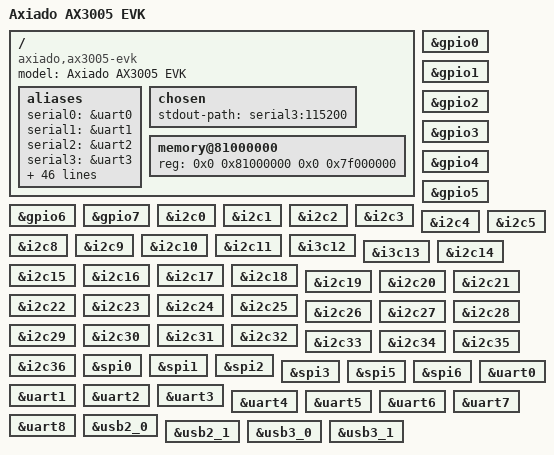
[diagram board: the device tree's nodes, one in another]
// SPDX-License-Identifier: GPL-2.0+
/*
 * DTS file for Axiado AX3005 SoC based EVK
 * Copyright (c) 2026 Axiado Corporation.
 */

/dts-v1/;

#include "ax3005.dtsi"

/ {
	model = "Axiado AX3005 EVK";
	compatible = "axiado,ax3005-evk", "axiado,ax3005";
	#address-cells = <2>;
	#size-cells = <2>;

	aliases {
		serial0 = &uart0;
		serial1 = &uart1;
		serial2 = &uart2;
		serial3 = &uart3;
		serial4 = &uart4;
		serial5 = &uart5;
		serial6 = &uart6;
		serial7 = &uart7;
		serial8 = &uart8;
		i2c0 = &i2c0;
		i2c1 = &i2c1;
		i2c2 = &i2c2;
		i2c3 = &i2c3;
		i2c4 = &i2c4;
		i2c5 = &i2c5;
		i2c8 = &i2c8;
		i2c9 = &i2c9;
		i2c10 = &i2c10;
		i2c11 = &i2c11;
		i2c12 = &i3c12;
		i2c13 = &i3c13;
		i2c14 = &i2c14;
		i2c15 = &i2c15;
		i2c16 = &i2c16;
		i2c17 = &i2c17;
		i2c18 = &i2c18;
		i2c19 = &i2c19;
		i2c20 = &i2c20;
		i2c21 = &i2c21;
		i2c22 = &i2c22;
		i2c23 = &i2c23;
		i2c24 = &i2c24;
		i2c25 = &i2c25;
		i2c26 = &i2c26;
		i2c27 = &i2c27;
		i2c28 = &i2c28;
		i2c29 = &i2c29;
		i2c30 = &i2c30;
		i2c31 = &i2c31;
		i2c32 = &i2c32;
		i2c33 = &i2c33;
		i2c34 = &i2c34;
		i2c35 = &i2c35;
		i2c36 = &i2c36;
		spi0 = &spi0;
		spi1 = &spi1;
		spi2 = &spi2;
		spi3 = &spi3;
		spi5 = &spi5;
		spi6 = &spi6;
	};

	chosen {
		stdout-path = "serial3:115200";
	};

	memory@81000000 {
		device_type = "memory";
		/* Cortex-A53 will use following memory map */
		reg = <0x0 0x81000000 0x0 0x7f000000>;
	};
};

&gpio0 {
	status = "okay";
};

&gpio1 {
	status = "okay";
};

&gpio2 {
	status = "okay";
};

&gpio3 {
	status = "okay";
};

&gpio4 {
	status = "okay";
};

&gpio5 {
	status = "okay";
};

&gpio6 {
	status = "okay";
};

&gpio7 {
	status = "okay";
};

&i2c0 {
	status = "okay";
};

&i2c1 {
	status = "okay";
};

&i2c2 {
	status = "okay";
};

&i2c3 {
	status = "okay";
};

&i2c4 {
	status = "okay";
};

&i2c5 {
	status = "okay";
};

&i2c8 {
	status = "okay";
};

&i2c9 {
	status = "okay";
};

&i2c10 {
	status = "okay";
};

&i2c11 {
	status = "okay";
};

&i3c12 {
	status = "okay";
};

&i3c13 {
	status = "okay";
};

&i2c14 {
	status = "okay";
};

&i2c15 {
	status = "okay";
};

&i2c16 {
	status = "okay";
};

&i2c17 {
	status = "okay";
};

&i2c18 {
	status = "okay";
};

&i2c19 {
	status = "okay";
};

&i2c20 {
	status = "okay";
};

&i2c21 {
	status = "okay";
};

&i2c22 {
	status = "okay";
};

&i2c23 {
	status = "okay";
};

&i2c24 {
	status = "okay";
};

&i2c25 {
	status = "okay";
};

&i2c26 {
	status = "okay";
};

&i2c27 {
	status = "okay";
};

&i2c28 {
	status = "okay";
};

&i2c29 {
	status = "okay";
};

&i2c30 {
	status = "okay";
};

&i2c31 {
	status = "okay";
};

&i2c32 {
	status = "okay";
};

&i2c33 {
	status = "okay";
};

&i2c34 {
	status = "okay";
};

&i2c35 {
	status = "okay";
};

&i2c36 {
	status = "okay";
};

&spi0 {
	status = "okay";
};

&spi1 {
	status = "okay";
};

&spi2 {
	status = "okay";
};

&spi3 {
	status = "okay";
};

&spi5 {
	status = "okay";
};

&spi6 {
	status = "okay";
};

&uart0 {
	status = "okay";
};

&uart1 {
	status = "okay";
};

&uart2 {
	status = "okay";
};

&uart3 {
	status = "okay";
};

&uart4 {
	status = "okay";
};

&uart5 {
	status = "okay";
};

&uart6 {
	status = "okay";
};

&uart7 {
	status = "okay";
};

&uart8 {
	status = "okay";
};

&usb2_0 {
	status = "okay";
};

&usb2_1 {
	status = "okay";
};

&usb3_0 {
	status = "okay";
};

&usb3_1 {
	status = "okay";
};
